# F28x7x_emif2_config_regs register map
Vendor: Texas Instruments
Peripheral module from a debugger description file (folder C2000).
Address unit: 16 bits
Registers are 32-bit, read-write, no defined reset value unless marked. A register's access mark holds for its fields unless they carry their own. Offsets are as the file gives them; lines under a group give offsets from that group; [hi:lo] are bit positions; {n}, {i} and the like mark numbered series; 'fields as' and 'values as' point back to an identical list; <NAME> marks a mode.

## EMIF2_CONFIG_REGS — EMIF2 CONFIG Registers
0x00 EMIF2LOCK — EMIF2 Config Lock Register
  [0] LOCK_EMIF2 — EMIF2 access protection and master select permanent lock
0x02 EMIF2COMMIT access not given — EMIF2 Config Lock Commit Register
  [0] COMMIT_EMIF2 — EMIF2 access protection and master select permanent lock (access R/SOnce)
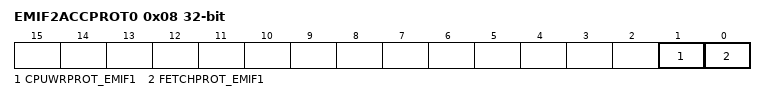
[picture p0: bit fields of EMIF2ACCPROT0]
0x08 EMIF2ACCPROT0 — EMIF2 Config Register 0
  [1] CPUWRPROT_EMIF1 — CPU WR Protection For EMIF2
  [0] FETCHPROT_EMIF1 — Fetch Protection For EMIF2
